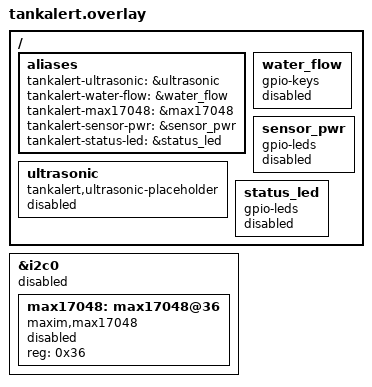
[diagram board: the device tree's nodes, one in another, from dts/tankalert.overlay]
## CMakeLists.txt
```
# SPDX-License-Identifier: Apache-2.0

cmake_minimum_required(VERSION 3.20.0)

# Allow custom TankAlert board definitions in boards/
list(APPEND BOARD_ROOT ${CMAKE_CURRENT_SOURCE_DIR}/boards)

find_package(Zephyr REQUIRED HINTS $ENV{ZEPHYR_BASE})
project(tankalert)

target_sources(app PRIVATE
	src/main.c
)

zephyr_include_directories(include)
```

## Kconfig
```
# SPDX-License-Identifier: Apache-2.0

mainmenu "TankAlert configuration"

source "Kconfig.pins"
```

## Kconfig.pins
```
# SPDX-License-Identifier: Apache-2.0

menu "TankAlert hardware pins"

config TANKALERT_PIN_ULTRASONIC_TRIG
	int "Ultrasonic TRIG GPIO (-1 = unassigned)"
	default -1
	help
	  GPIO number for the ultrasonic sensor TRIG line.
	  Set to -1 until the schematic pin is confirmed.

config TANKALERT_PIN_ULTRASONIC_ECHO
	int "Ultrasonic ECHO GPIO (-1 = unassigned)"
	default -1
	help
	  GPIO number for the ultrasonic sensor ECHO line.
	  Set to -1 until the schematic pin is confirmed.
	  If the sensor uses UART instead, leave unassigned and use UART.

config TANKALERT_PIN_WATER_FLOW
	int "Water flow GPIO input (-1 = unassigned)"
	default -1
	help
	  GPIO number for the external water-flow ON/OFF input.

config TANKALERT_PIN_MAX17048_SDA
	int "MAX17048 I2C SDA GPIO (-1 = unassigned)"
	default -1
	help
	  GPIO number for MAX17048 I2C SDA.

config TANKALERT_PIN_MAX17048_SCL
	int "MAX17048 I2C SCL GPIO (-1 = unassigned)"
	default -1
	help
	  GPIO number for MAX17048 I2C SCL.

config TANKALERT_PIN_SENSOR_PWR_EN
	int "Sensor power enable GPIO (-1 = unassigned)"
	default -1
	help
	  GPIO that enables the sensor power rail.

config TANKALERT_PIN_STATUS_LED
	int "Status LED GPIO (-1 = unassigned)"
	default -1
	help
	  Optional status LED GPIO.

endmenu
```

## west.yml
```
# TankAlert Zephyr west manifest
# SPDX-License-Identifier: Apache-2.0
#
# Expected west workspace layout:
#   <workspace>/
#   ├── zephyr/     <- fetched by west update
#   └── tankalert/  <- this repository (west manifest)
#
# Initialize from the workspace directory:
#   west init -l tankalert
#   west update
#   west blobs fetch hal_espressif

manifest:
  version: 1.2

  self:
    path: tankalert

  remotes:
    - name: zephyrproject-rtos
      url-base: https://github.com/zephyrproject-rtos

  projects:
    - name: zephyr
      remote: zephyrproject-rtos
      revision: v4.1.0
      west-commands: scripts/west-commands.yml
      import: true
```

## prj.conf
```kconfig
# SPDX-License-Identifier: Apache-2.0
#
# TankAlert Zephyr configuration
# Subsystems below are enabled for future modules; only logging/GPIO/UART
# are required for the current heartbeat firmware.

# --- Kernel / logging ---
CONFIG_LOG=y
CONFIG_LOG_DEFAULT_LEVEL=3
CONFIG_PRINTK=y

CONFIG_MAIN_STACK_SIZE=4096
CONFIG_SYSTEM_WORKQUEUE_STACK_SIZE=2048

# --- Console (ESP32 UART0) ---
CONFIG_CONSOLE=y
CONFIG_UART_CONSOLE=y
CONFIG_SERIAL=y

# --- GPIO (water flow, sensor power, ultrasonic TRIG/ECHO) ---
CONFIG_GPIO=y

# --- I2C (MAX17048 fuel gauge) ---
CONFIG_I2C=y

# --- UART (optional JSN-SR04T serial mode) ---
CONFIG_UART_INTERRUPT_DRIVEN=y

# --- ADC (reserved for future analog front-end; not used yet) ---
# CONFIG_ADC=y

# --- Power management (light sleep / deep sleep scheduling) ---
CONFIG_PM=y
CONFIG_PM_DEVICE=y

# --- Time / SNTP (RTC sync for sample timestamps) ---
CONFIG_POSIX_CLOCK=y
CONFIG_SNTP=y

# --- Persistent storage (NVS + settings for credentials and history) ---
CONFIG_FLASH=y
CONFIG_FLASH_MAP=y
CONFIG_NVS=y
CONFIG_SETTINGS=y
CONFIG_SETTINGS_NVS=y

# --- Networking stack (Wi-Fi + MQTT planned) ---
CONFIG_NETWORKING=y
CONFIG_NET_IPV4=y
CONFIG_NET_DHCPV4=y
CONFIG_NET_TCP=y
CONFIG_NET_UDP=y
CONFIG_NET_SOCKETS=y
CONFIG_NET_MGMT=y
CONFIG_NET_MGMT_EVENT=y
CONFIG_NET_CONNECTION_MANAGER=y

# --- Wi-Fi station mode ---
CONFIG_WIFI=y
CONFIG_WIFI_USAGE_MODE_STA=y

# ESP32 Wi-Fi integration (board DT enables esp32-wifi)
CONFIG_ESP32_WIFI_STA_AUTO_DHCPV4=y

# Network buffer pools (tune when MQTT is added)
CONFIG_NET_PKT_RX_COUNT=10
CONFIG_NET_PKT_TX_COUNT=10
CONFIG_NET_BUF_RX_COUNT=20
CONFIG_NET_BUF_TX_COUNT=20
CONFIG_NET_TX_STACK_SIZE=2048
CONFIG_NET_RX_STACK_SIZE=2048

# --- MQTT client library (not used by heartbeat yet) ---
CONFIG_MQTT_LIB=y

# Wi-Fi credentials: create wifi_credentials.conf locally (gitignored)
# CONFIG_WIFI_CREDENTIALS=y
# CONFIG_WIFI_CREDENTIALS_STATIC_SSID="your-ssid"
# CONFIG_WIFI_CREDENTIALS_STATIC_PASSWORD="your-password"
```

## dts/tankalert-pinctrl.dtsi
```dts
/*
 * SPDX-License-Identifier: Apache-2.0
 *
 * TankAlert pin-control placeholders.
 *
 * IMPORTANT: GPIO numbers are NOT assigned yet.
 * After schematic review, set the pin numbers below and set status = "okay"
 * on the relevant nodes in tankalert.overlay.
 *
 * Pin assignment checklist (update before enabling hardware):
 *   - TANKALERT_PIN_ULTRASONIC_TRIG   : ultrasonic TRIG (GPIO bit-bang)
 *   - TANKALERT_PIN_ULTRASONIC_ECHO   : ultrasonic ECHO (GPIO capture)
 *   - TANKALERT_PIN_WATER_FLOW        : water-flow digital input
 *   - TANKALERT_PIN_MAX17048_SDA      : MAX17048 I2C SDA
 *   - TANKALERT_PIN_MAX17048_SCL      : MAX17048 I2C SCL
 *   - TANKALERT_PIN_SENSOR_PWR_EN     : sensor rail enable (active level TBD)
 *   - TANKALERT_PIN_STATUS_LED        : optional status LED (active level TBD)
 *
 * Kconfig mirrors these assignments in Kconfig.pins for runtime/C code access.
 */

/ {
	chosen {
		/* Override when a dedicated TankAlert UART is wired for the sensor */
		/* zephyr,console = &uart0; */
	};
};

/*
 * Example pinctrl fragment (uncomment and fill after pin assignment):
 *
 * &pinctrl {
 *     i2c0_default: i2c0_default {
 *         group1 {
 *             pinmux = <TANKALERT_PIN_MAX17048_SDA>,
 *                      <TANKALERT_PIN_MAX17048_SCL>;
 *             bias-pull-up;
 *         };
 *     };
 * };
 */
```

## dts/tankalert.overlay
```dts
/*
 * SPDX-License-Identifier: Apache-2.0
 *
 * TankAlert application DeviceTree overlay.
 *
 * Peripheral nodes are declared here but left disabled until GPIO/I2C pins
 * are confirmed on the custom PCB. See dts/tankalert-pinctrl.dtsi and
 * Kconfig.pins for the single place to assign pin numbers.
 */

#include <dt-bindings/gpio/gpio.h>

/ {
	aliases {
		tankalert-ultrasonic = &ultrasonic;
		tankalert-water-flow = &water_flow;
		tankalert-max17048 = &max17048;
		tankalert-sensor-pwr = &sensor_pwr;
		tankalert-status-led = &status_led;
	};

	/*
	 * Ultrasonic level sensor (JSN-SR04T candidate).
	 * Driver will use Zephyr GPIO or UART APIs depending on final wiring.
	 */
	ultrasonic: ultrasonic {
		compatible = "tankalert,ultrasonic-placeholder";
		status = "disabled";
		/* trig-gpios = <&gpio0 TANKALERT_PIN_ULTRASONIC_TRIG GPIO_ACTIVE_HIGH>; */
		/* echo-gpios = <&gpio0 TANKALERT_PIN_ULTRASONIC_ECHO GPIO_ACTIVE_HIGH>; */
	};

	/* External water-flow switch / pulse input */
	water_flow: water_flow {
		compatible = "gpio-keys";
		status = "disabled";
		/* flow-gpios = <&gpio0 TANKALERT_PIN_WATER_FLOW (GPIO_PULL_UP | GPIO_ACTIVE_LOW)>; */
	};

	/* Sensor power enable (ultrasonic + front-end rails) */
	sensor_pwr: sensor_pwr {
		compatible = "gpio-leds";
		status = "disabled";
		/* pwr-gpios = <&gpio0 TANKALERT_PIN_SENSOR_PWR_EN GPIO_ACTIVE_HIGH>; */
	};

	/* Optional board status LED */
	status_led: status_led {
		compatible = "gpio-leds";
		status = "disabled";
		/* led-gpios = <&gpio0 TANKALERT_PIN_STATUS_LED GPIO_ACTIVE_LOW>; */
	};
};

/*
 * MAX17048 fuel gauge on I2C.
 * Enable after SDA/SCL pins are assigned in tankalert-pinctrl.dtsi.
 */
&i2c0 {
	status = "disabled";
	/* Assign pinctrl in tankalert-pinctrl.dtsi, then uncomment:
	 * pinctrl-0 = <&i2c0_default>;
	 * pinctrl-names = "default";
	 */

	max17048: max17048@36 {
		compatible = "maxim,max17048";
		reg = <0x36>;
		status = "disabled";
	};
};
```

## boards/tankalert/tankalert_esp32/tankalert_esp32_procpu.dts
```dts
/*
 * SPDX-License-Identifier: Apache-2.0
 *
 * TankAlert ESP32-WROOM board (PROCPU).
 *
 * Based on Espressif ESP32-DevKitC. Pin assignments for TankAlert-specific
 * peripherals are defined in dts/tankalert.overlay and dts/tankalert-pinctrl.dtsi.
 * Update those files once schematic GPIO routing is confirmed.
 */

/dts-v1/;

#include <espressif/esp32/esp32_devkitc/esp32_devkitc_procpu.dts>
#include "../../dts/tankalert-pinctrl.dtsi"
#include "../../dts/tankalert.overlay"
```

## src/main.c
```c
/*
 * SPDX-License-Identifier: Apache-2.0
 *
 * TankAlert - minimal heartbeat application.
 * Future modules (sensors, battery, network, storage, power) live under app/.
 */

#include <zephyr/kernel.h>
#include <zephyr/sys/printk.h>

#define HEARTBEAT_INTERVAL_MS 5000

int main(void)
{
	uint32_t count;

	printk("TankAlert firmware starting\n");
	printk("Board: %s\n", CONFIG_BOARD);

	for (count = 0; ; count++) {
		printk("heartbeat %u\n", count);
		k_sleep(K_MSEC(HEARTBEAT_INTERVAL_MS));
	}

	return 0;
}
```
